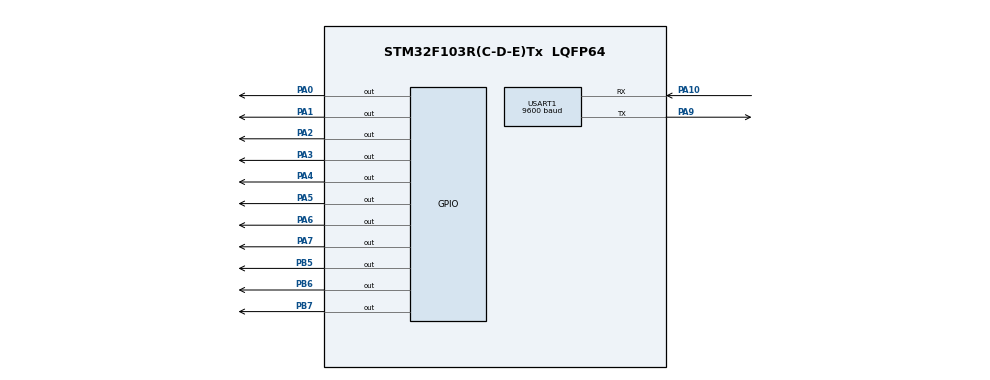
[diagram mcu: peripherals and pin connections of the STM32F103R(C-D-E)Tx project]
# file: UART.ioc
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Mcu.Family=STM32F1
Mcu.Name=STM32F103R(C-D-E)Tx
Mcu.Package=LQFP64
NVIC.PriorityGroup=NVIC_PRIORITYGROUP_4
NVIC.USART1_IRQn=true\:1\:0\:true
PA0-WKUP.Signal=GPIO_Output
PA1.Signal=GPIO_Output
PA10.GPIO_PuPd=GPIO_PULLUP
PA10.Mode=Asynchronous
PA10.Signal=USART1_RX
PA2.Signal=GPIO_Output
PA3.Signal=GPIO_Output
PA4.Signal=GPIO_Output
PA5.Signal=GPIO_Output
PA6.Signal=GPIO_Output
PA7.Signal=GPIO_Output
PA9.Mode=Asynchronous
PA9.Signal=USART1_TX
PB5.Signal=GPIO_Output
PB6.Signal=GPIO_Output
PB7.Signal=GPIO_Output
PD0-OSC_IN.Mode=HSE-External-Oscillator
PD0-OSC_IN.Signal=RCC_OSC_IN
PD1-OSC_OUT.Mode=HSE-External-Oscillator
PD1-OSC_OUT.Signal=RCC_OSC_OUT
ProjectManager.TargetToolchain=EWARM
RCC.APB1Freq_Value=8000000
RCC.APB2Freq_Value=8000000
RCC.PLLSourceVirtual=RCC_PLLSOURCE_HSE
RCC.SYSCLKSource=RCC_SYSCLKSOURCE_HSE
RCC.USBFreq_Value=16000000
USART1.BaudRate=9600
board=UART

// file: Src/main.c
/**
  ******************************************************************************
  * File Name          : main.c
  * Description        : Main program body
  ******************************************************************************
  *
  * COPYRIGHT(c) 2016 STMicroelectronics
  *
  * Redistribution and use in source and binary forms, with or without modification,
  * are permitted provided that the following conditions are met:
  *   1. Redistributions of source code must retain the above copyright notice,
  *      this list of conditions and the following disclaimer.
  *   2. Redistributions in binary form must reproduce the above copyright notice,
  *      this list of conditions and the following disclaimer in the documentation
  *      and/or other materials provided with the distribution.
  *   3. Neither the name of STMicroelectronics nor the names of its contributors
  *      may be used to endorse or promote products derived from this software
  *      without specific prior written permission.
  *
  * THIS SOFTWARE IS PROVIDED BY THE COPYRIGHT HOLDERS AND CONTRIBUTORS "AS IS"
  * AND ANY EXPRESS OR IMPLIED WARRANTIES, INCLUDING, BUT NOT LIMITED TO, THE
  * IMPLIED WARRANTIES OF MERCHANTABILITY AND FITNESS FOR A PARTICULAR PURPOSE ARE
  * DISCLAIMED. IN NO EVENT SHALL THE COPYRIGHT HOLDER OR CONTRIBUTORS BE LIABLE
  * FOR ANY DIRECT, INDIRECT, INCIDENTAL, SPECIAL, EXEMPLARY, OR CONSEQUENTIAL
  * DAMAGES (INCLUDING, BUT NOT LIMITED TO, PROCUREMENT OF SUBSTITUTE GOODS OR
  * SERVICES; LOSS OF USE, DATA, OR PROFITS; OR BUSINESS INTERRUPTION) HOWEVER
  * CAUSED AND ON ANY THEORY OF LIABILITY, WHETHER IN CONTRACT, STRICT LIABILITY,
  * OR TORT (INCLUDING NEGLIGENCE OR OTHERWISE) ARISING IN ANY WAY OUT OF THE USE
  * OF THIS SOFTWARE, EVEN IF ADVISED OF THE POSSIBILITY OF SUCH DAMAGE.
  *
  ******************************************************************************
  */
#include "stm32f1xx_hal.h"

/* USER CODE BEGIN Includes */

#include <stdio.h>

/* USER CODE END Includes */

UART_HandleTypeDef huart1;

/* USER CODE BEGIN PV */
/* Private variables ---------------------------------------------------------*/

unsigned char i;
char data[17];

/* USER CODE END PV */

void SystemClock_Config(void);
static void MX_GPIO_Init(void);
static void MX_USART1_UART_Init(void);

/* USER CODE BEGIN PFP */
/* Private function prototypes -----------------------------------------------*/

/* USER CODE END PFP */

/* USER CODE BEGIN 0 */

void put_str(char *str)
{
  while(*str!=0)
  {
    HAL_UART_Transmit(&huart1,(unsigned char*)str, 1, 10);
    str++;
  }
}

/* USER CODE END 0 */

int main(void)
{

  /* MCU Configuration----------------------------------------------------------*/

  /* Reset of all peripherals, Initializes the Flash interface and the Systick. */
  HAL_Init();

  /* Configure the system clock */
  SystemClock_Config();

  /* Initialize all configured peripherals */
  MX_GPIO_Init();
  MX_USART1_UART_Init();

  /* Infinite loop */
  /* USER CODE BEGIN WHILE */

  while (1)
  {

    sprintf(data,"Value=%d\n",i);
    put_str(data);
    HAL_Delay(500);
    i++;

  /* USER CODE END WHILE */

  }

}

/** System Clock Configuration
*/
void SystemClock_Config(void)
{

  RCC_OscInitTypeDef RCC_OscInitStruct;
  RCC_ClkInitTypeDef RCC_ClkInitStruct;

  RCC_OscInitStruct.OscillatorType = RCC_OSCILLATORTYPE_HSE;
  RCC_OscInitStruct.HSEState = RCC_HSE_ON;
  RCC_OscInitStruct.PLL.PLLState = RCC_PLL_NONE;
  HAL_RCC_OscConfig(&RCC_OscInitStruct);

  RCC_ClkInitStruct.ClockType = RCC_CLOCKTYPE_SYSCLK;
  RCC_ClkInitStruct.SYSCLKSource = RCC_SYSCLKSOURCE_HSE;
  RCC_ClkInitStruct.AHBCLKDivider = RCC_SYSCLK_DIV1;
  RCC_ClkInitStruct.APB1CLKDivider = RCC_HCLK_DIV1;
  RCC_ClkInitStruct.APB2CLKDivider = RCC_HCLK_DIV1;
  HAL_RCC_ClockConfig(&RCC_ClkInitStruct, FLASH_LATENCY_0);

  HAL_SYSTICK_Config(HAL_RCC_GetHCLKFreq()/1000);

  HAL_SYSTICK_CLKSourceConfig(SYSTICK_CLKSOURCE_HCLK);

  /* SysTick_IRQn interrupt configuration */
  HAL_NVIC_SetPriority(SysTick_IRQn, 0, 0);
}

/* USART1 init function */
void MX_USART1_UART_Init(void)
{

  huart1.Instance = USART1;
  huart1.Init.BaudRate = 9600;
  huart1.Init.WordLength = UART_WORDLENGTH_8B;
  huart1.Init.StopBits = UART_STOPBITS_1;
  huart1.Init.Parity = UART_PARITY_NONE;
  huart1.Init.Mode = UART_MODE_TX_RX;
  huart1.Init.HwFlowCtl = UART_HWCONTROL_NONE;
  huart1.Init.OverSampling = UART_OVERSAMPLING_16;
  HAL_UART_Init(&huart1);

}

/** Configure pins as
        * Analog
        * Input
        * Output
        * EVENT_OUT
        * EXTI
*/
void MX_GPIO_Init(void)
{

  GPIO_InitTypeDef GPIO_InitStruct;

  /* GPIO Ports Clock Enable */
  __GPIOD_CLK_ENABLE();
  __GPIOA_CLK_ENABLE();
  __GPIOB_CLK_ENABLE();

  /*Configure GPIO pins : PA0 PA1 PA2 PA3
                           PA4 PA5 PA6 PA7 */
  GPIO_InitStruct.Pin = GPIO_PIN_0|GPIO_PIN_1|GPIO_PIN_2|GPIO_PIN_3
                          |GPIO_PIN_4|GPIO_PIN_5|GPIO_PIN_6|GPIO_PIN_7;
  GPIO_InitStruct.Mode = GPIO_MODE_OUTPUT_PP;
  GPIO_InitStruct.Speed = GPIO_SPEED_LOW;
  HAL_GPIO_Init(GPIOA, &GPIO_InitStruct);

  /*Configure GPIO pins : PB5 PB6 PB7 */
  GPIO_InitStruct.Pin = GPIO_PIN_5|GPIO_PIN_6|GPIO_PIN_7;
  GPIO_InitStruct.Mode = GPIO_MODE_OUTPUT_PP;
  GPIO_InitStruct.Speed = GPIO_SPEED_LOW;
  HAL_GPIO_Init(GPIOB, &GPIO_InitStruct);

}

/************************ (C) COPYRIGHT STMicroelectronics *****END OF FILE****/
